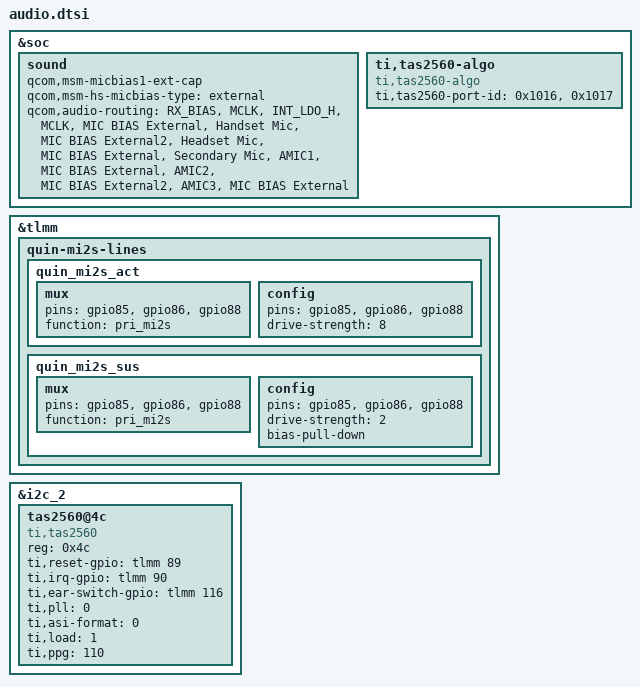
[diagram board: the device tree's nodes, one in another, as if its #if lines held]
&soc {
	sound {
		/delete-property/ qcom,cdc-us-eu-gpios;
		/delete-property/ qcom,cdc-us-euro-gpios;
		qcom,msm-micbias1-ext-cap;
		/delete-property/ qcom,msm-micbias2-ext-cap;
		qcom,msm-hs-micbias-type = "external";
		qcom,audio-routing =
			"RX_BIAS", "MCLK",
			"INT_LDO_H", "MCLK",
			"MIC BIAS External", "Handset Mic",
			"MIC BIAS External2", "Headset Mic",
			"MIC BIAS External", "Secondary Mic",
			"AMIC1", "MIC BIAS External",
			"AMIC2", "MIC BIAS External2",
			"AMIC3", "MIC BIAS External";
#ifndef DEVICE_JETER
		/delete-property/ qcom,quin-mi2s-gpios;
#endif
	};
};

#ifdef DEVICE_JETER
&soc {
	ti,tas2560-algo {
		compatible = "ti,tas2560-algo";
		ti,tas2560-port-id = <0x1016>, <0x1017>;
	};
};

&tlmm{
	quin-mi2s-lines {
		quin_mi2s_act: quin_mi2s_act {
			mux {
				pins = "gpio85", "gpio86", "gpio88";
				function = "pri_mi2s";
			};
			config {
				pins = "gpio85", "gpio86", "gpio88";
				drive-strength = <8>;
			};
		};
		quin_mi2s_sus: quin_mi2s_sus {
			mux {
				pins = "gpio85", "gpio86", "gpio88";
				function = "pri_mi2s";
			};
			config {
				pins = "gpio85", "gpio86", "gpio88";
				drive-strength = <2>;
				bias-pull-down;
			};
		};
	};
};

&i2c_2 {
	tas2560@4c {
			compatible = "ti,tas2560";
			reg = <0x4c>;
			ti,reset-gpio = <&tlmm 89 0>;
			ti,irq-gpio = <&tlmm 90 0>;
			ti,ear-switch-gpio = <&tlmm 116 0>;
			ti,pll = <0>; /* refer to tas2560.h for more details */
			ti,asi-format = <0>; /* 0, i2S; 1, DSP;  */
			ti,load = <1>; /* 0, 8Ohm; 1, 6Ohm; 2, 4Ohm */
			ti,ppg = <110>; /*attenuation,0(-110db)~110(0db) */
			status = "ok";
	};
};
#endif
